# nrf54h20_sysctrl register map
Vendor: Nordic Semiconductor; Series: nRF54h; File version: 1
Registers are 32-bit, read-write, reset 0x0 unless marked. A register's access mark holds for its fields unless they carry their own. Offsets are from the block's base; [hi:lo] are bit positions; lines under a group give offsets from that group; {n}, {i} and the like mark numbered series; 'fields as' and 'values as' point back to an identical list.

## GRCCONF
Base 0x5F940000
{0x100+4i} EVENTS_GRCPERIPH0[{i}] (i=0..31) — Description collection: Event indicating that interrupt triggered for GRC peripheral identifier [n]
  [0] EVENTS_GRCPERIPH0 — Event indicating that interrupt triggered for GRC peripheral identifier [n]
    0=NotGenerated (Event not generated); 1=Generated (Event generated)
{0x180+4i} EVENTS_GRCPERIPH1[{i}] (i=0..31) — Description collection: Event indicating that interrupt triggered for GRC peripheral identifier [32 + n]
  [0] EVENTS_GRCPERIPH1 — Event indicating that interrupt triggered for GRC peripheral identifier [32 + n]
    values as EVENTS_GRCPERIPH0[0].EVENTS_GRCPERIPH0
0x200 EVENTS_SYSTEMOFFREADY — Event indicating that the device is ready to go to System OFF
  [0] EVENTS_SYSTEMOFFREADY
    values as EVENTS_GRCPERIPH0[0].EVENTS_GRCPERIPH0
0x204 EVENTS_SYSTEMOFFNOTREADY — Event indicating that the device is not ready to go to System OFF
  [0] EVENTS_SYSTEMOFFNOTREADY
    values as EVENTS_GRCPERIPH0[0].EVENTS_GRCPERIPH0
0x208 EVENTS_SYSTEMOFFLOCALDOMAINOFF — Event indicating that SYSTEMOFF is non-zero and all local power domains are powered off with the possible exception of Secure Domain depending on the value of SYSTEMOFF.SYSTEMOFFIGNORESECDOM.
  [0] EVENTS_SYSTEMOFFLOCALDOMAINOFF
    values as EVENTS_GRCPERIPH0[0].EVENTS_GRCPERIPH0
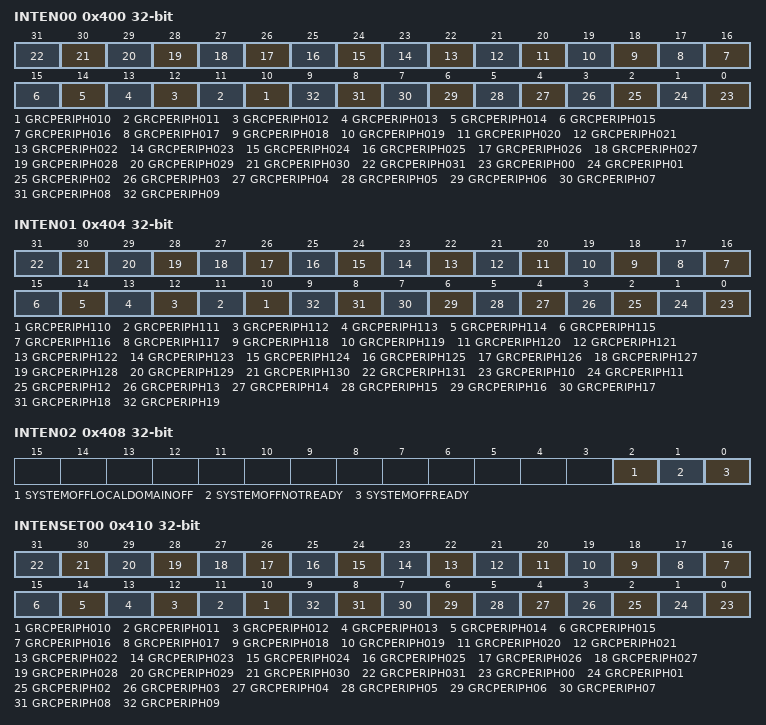
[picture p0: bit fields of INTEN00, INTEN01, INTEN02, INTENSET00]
0x400 INTEN00 — Enable or disable interrupt
  [all] fields
    0=Disabled; 1=Enabled
  [n] GRCPERIPH{n:03} (n=10..31) — Enable or disable interrupt for event GRCPERIPH0[{n}]
  [n] GRCPERIPH{n:02} (n=0..9) — Enable or disable interrupt for event GRCPERIPH0[{n}]
0x404 INTEN01 — Enable or disable interrupt
  [all] fields
    0=Disabled; 1=Enabled
  [n-100] GRCPERIPH{n} (n=110..131) — Enable or disable interrupt for event GRCPERIPH1[{n-100}]
  [n-10] GRCPERIPH{n} (n=10..19) — Enable or disable interrupt for event GRCPERIPH1[{n-10}]
0x408 INTEN02 — Enable or disable interrupt
  [all] fields
    0=Disabled; 1=Enabled
  [2] SYSTEMOFFLOCALDOMAINOFF — Enable or disable interrupt for event SYSTEMOFFLOCALDOMAINOFF
  [1] SYSTEMOFFNOTREADY — Enable or disable interrupt for event SYSTEMOFFNOTREADY
  [0] SYSTEMOFFREADY — Enable or disable interrupt for event SYSTEMOFFREADY
0x410 INTENSET00 — Enable interrupt
  [all] fields
    on read: 0=Disabled (Read: Disabled); 1=Enabled (Read: Enabled) | on write: 1=Set (Enable)
  [n] GRCPERIPH{n:03} (n=10..31) — Write '1' to enable interrupt for event GRCPERIPH0[{n}]
  [n] GRCPERIPH{n:02} (n=0..9) — Write '1' to enable interrupt for event GRCPERIPH0[{n}]
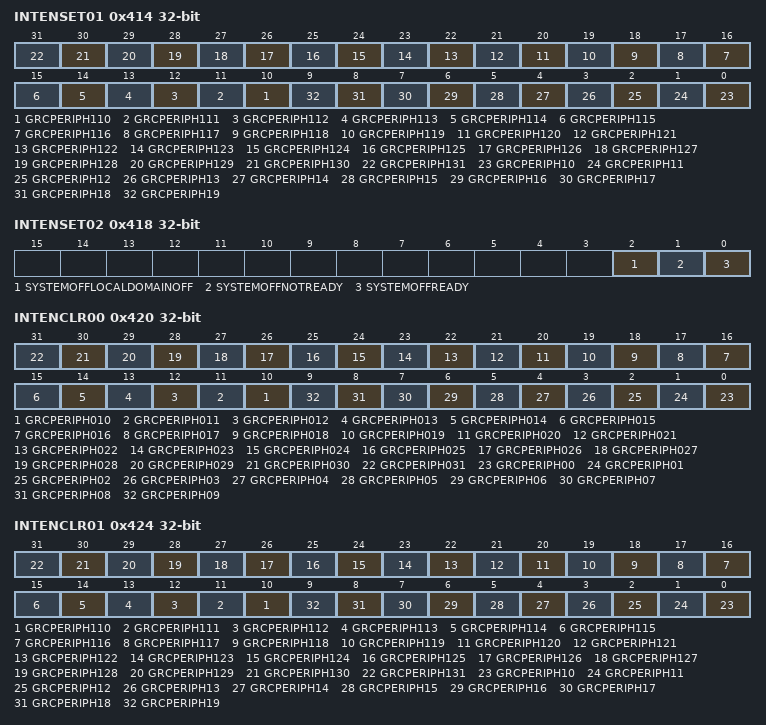
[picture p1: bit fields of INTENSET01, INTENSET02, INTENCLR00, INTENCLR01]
0x414 INTENSET01 — Enable interrupt
  [all] fields
    values as the fields of INTENSET00
  [n-100] GRCPERIPH{n} (n=110..131) — Write '1' to enable interrupt for event GRCPERIPH1[{n-100}]
  [n-10] GRCPERIPH{n} (n=10..19) — Write '1' to enable interrupt for event GRCPERIPH1[{n-10}]
0x418 INTENSET02 — Enable interrupt
  [all] fields
    values as the fields of INTENSET00
  [2] SYSTEMOFFLOCALDOMAINOFF — Write '1' to enable interrupt for event SYSTEMOFFLOCALDOMAINOFF
  [1] SYSTEMOFFNOTREADY — Write '1' to enable interrupt for event SYSTEMOFFNOTREADY
  [0] SYSTEMOFFREADY — Write '1' to enable interrupt for event SYSTEMOFFREADY
0x420 INTENCLR00 — Disable interrupt
  [all] fields
    on read: 0=Disabled (Read: Disabled); 1=Enabled (Read: Enabled) | on write: 1=Clear (Disable)
  [n] GRCPERIPH{n:03} (n=10..31) — Write '1' to disable interrupt for event GRCPERIPH0[{n}]
  [n] GRCPERIPH{n:02} (n=0..9) — Write '1' to disable interrupt for event GRCPERIPH0[{n}]
0x424 INTENCLR01 — Disable interrupt
  [all] fields
    values as the fields of INTENCLR00
  [n-100] GRCPERIPH{n} (n=110..131) — Write '1' to disable interrupt for event GRCPERIPH1[{n-100}]
  [n-10] GRCPERIPH{n} (n=10..19) — Write '1' to disable interrupt for event GRCPERIPH1[{n-10}]
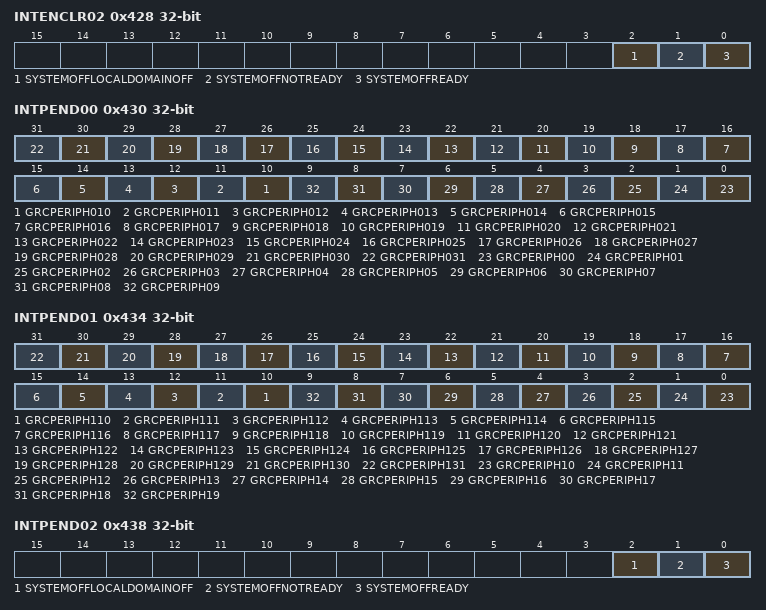
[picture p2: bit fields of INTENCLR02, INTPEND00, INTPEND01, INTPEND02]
0x428 INTENCLR02 — Disable interrupt
  [all] fields
    values as the fields of INTENCLR00
  [2] SYSTEMOFFLOCALDOMAINOFF — Write '1' to disable interrupt for event SYSTEMOFFLOCALDOMAINOFF
  [1] SYSTEMOFFNOTREADY — Write '1' to disable interrupt for event SYSTEMOFFNOTREADY
  [0] SYSTEMOFFREADY — Write '1' to disable interrupt for event SYSTEMOFFREADY
0x430 INTPEND00 ro — Pending interrupts
  [all] fields
    on read: 0=NotPending (Read: Not pending); 1=Pending (Read: Pending)
  [n] GRCPERIPH{n:03} (n=10..31) — Read pending status of interrupt for event GRCPERIPH0[{n}]
  [n] GRCPERIPH{n:02} (n=0..9) — Read pending status of interrupt for event GRCPERIPH0[{n}]
0x434 INTPEND01 ro — Pending interrupts
  [all] fields
    values as the fields of INTPEND00
  [n-100] GRCPERIPH{n} (n=110..131) — Read pending status of interrupt for event GRCPERIPH1[{n-100}]
  [n-10] GRCPERIPH{n} (n=10..19) — Read pending status of interrupt for event GRCPERIPH1[{n-10}]
0x438 INTPEND02 ro — Pending interrupts
  [all] fields
    values as the fields of INTPEND00
  [2] SYSTEMOFFLOCALDOMAINOFF — Read pending status of interrupt for event SYSTEMOFFLOCALDOMAINOFF
  [1] SYSTEMOFFNOTREADY — Read pending status of interrupt for event SYSTEMOFFNOTREADY
  [0] SYSTEMOFFREADY — Read pending status of interrupt for event SYSTEMOFFREADY
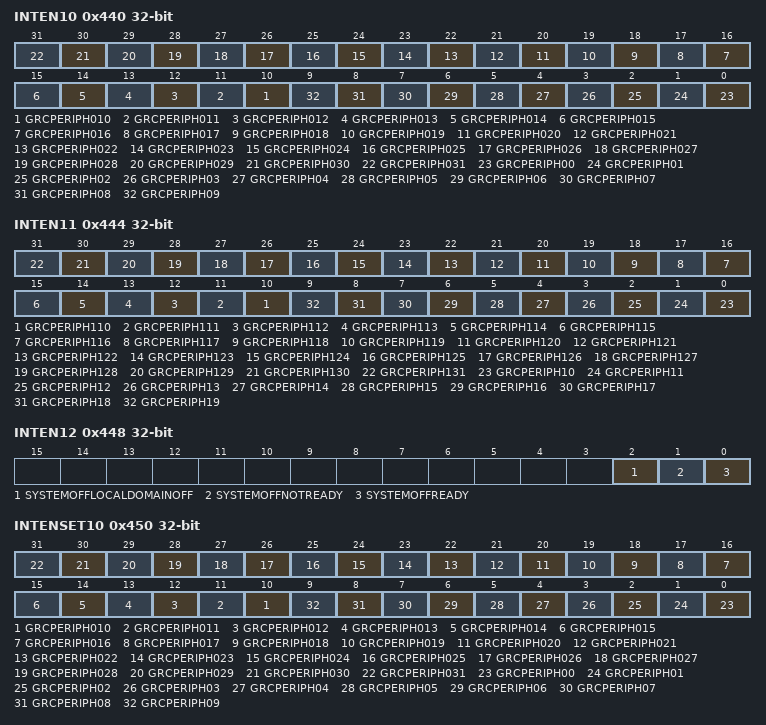
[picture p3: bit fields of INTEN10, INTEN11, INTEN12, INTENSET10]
0x440 INTEN10 — Enable or disable interrupt
  fields as INTEN00
0x444 INTEN11 — Enable or disable interrupt
  fields as INTEN01
0x448 INTEN12 — Enable or disable interrupt
  fields as INTEN02
0x450 INTENSET10 — Enable interrupt
  fields as INTENSET00
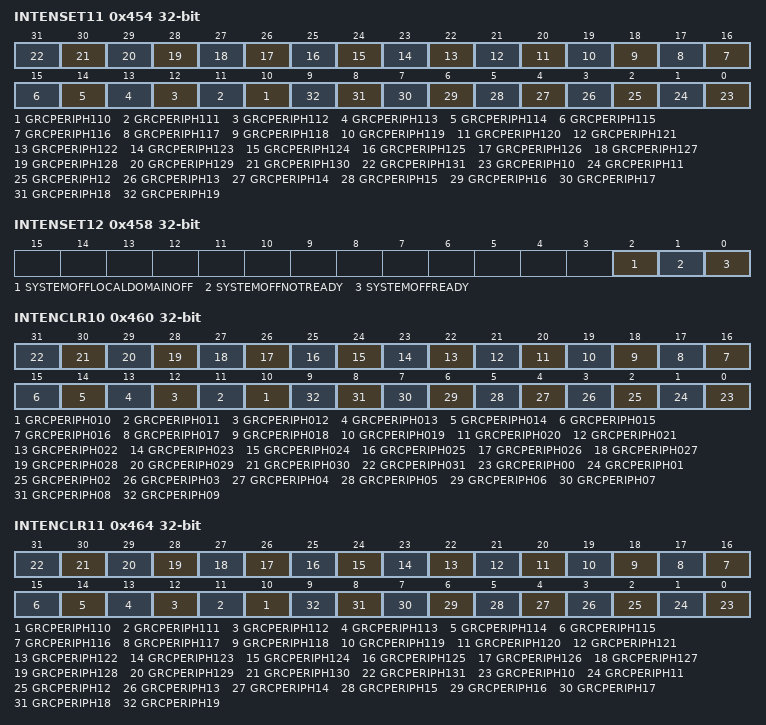
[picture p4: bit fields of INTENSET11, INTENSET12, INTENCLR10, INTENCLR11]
0x454 INTENSET11 — Enable interrupt
  fields as INTENSET01
0x458 INTENSET12 — Enable interrupt
  fields as INTENSET02
0x460 INTENCLR10 — Disable interrupt
  fields as INTENCLR00
0x464 INTENCLR11 — Disable interrupt
  fields as INTENCLR01
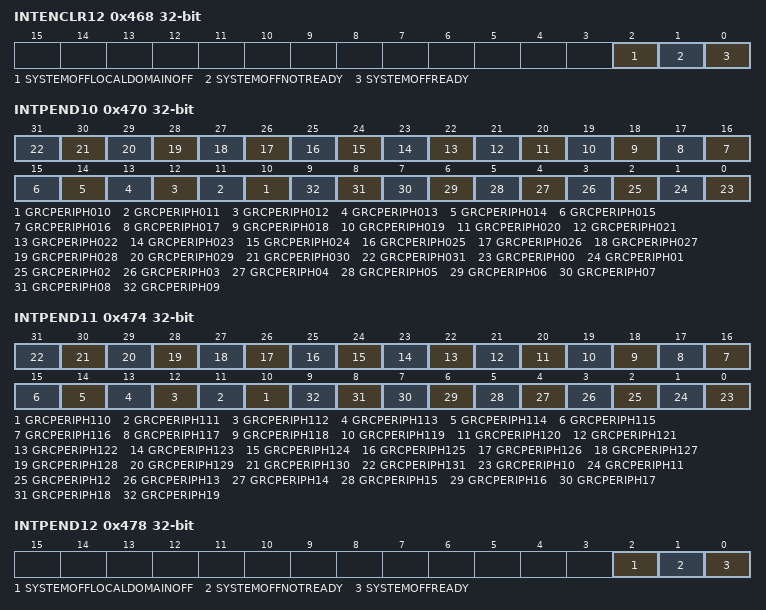
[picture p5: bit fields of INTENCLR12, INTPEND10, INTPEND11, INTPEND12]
0x468 INTENCLR12 — Disable interrupt
  fields as INTENCLR02
0x470 INTPEND10 ro — Pending interrupts
  fields as INTPEND00
0x474 INTPEND11 ro — Pending interrupts
  fields as INTPEND01
0x478 INTPEND12 ro — Pending interrupts
  fields as INTPEND02
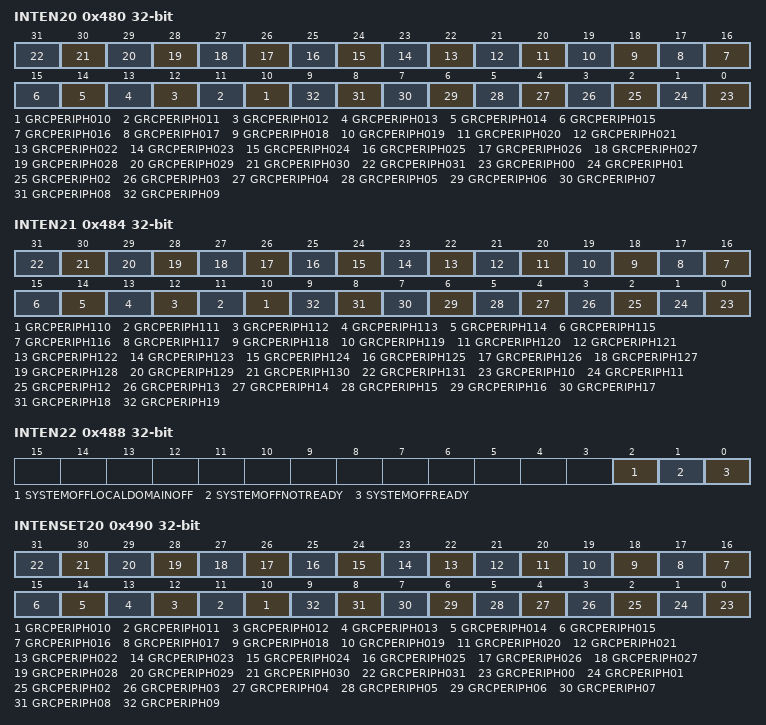
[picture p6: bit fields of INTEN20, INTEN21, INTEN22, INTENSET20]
0x480 INTEN20 — Enable or disable interrupt
  fields as INTEN00
0x484 INTEN21 — Enable or disable interrupt
  fields as INTEN01
0x488 INTEN22 — Enable or disable interrupt
  fields as INTEN02
0x490 INTENSET20 — Enable interrupt
  fields as INTENSET00
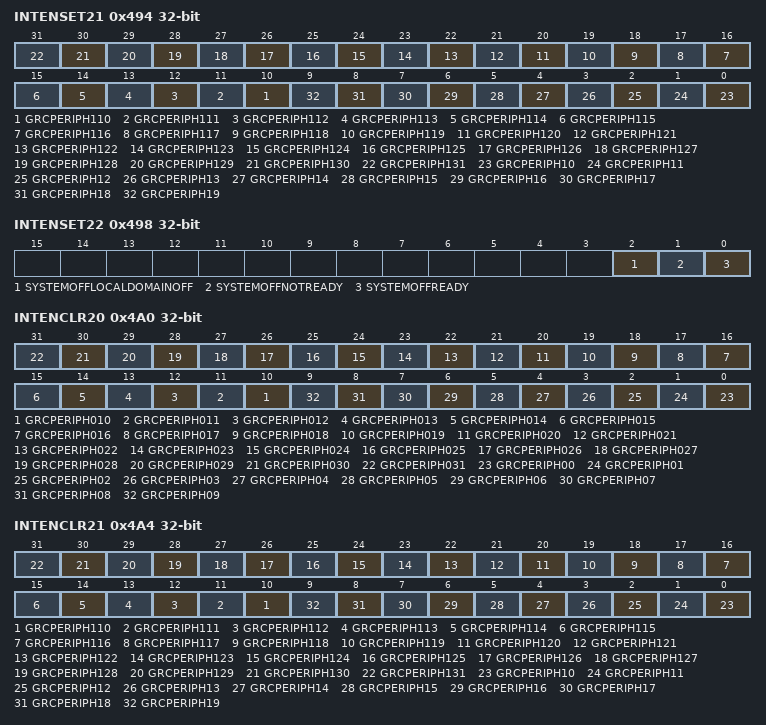
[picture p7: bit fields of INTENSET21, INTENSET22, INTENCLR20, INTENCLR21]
0x494 INTENSET21 — Enable interrupt
  fields as INTENSET01
0x498 INTENSET22 — Enable interrupt
  fields as INTENSET02
0x4A0 INTENCLR20 — Disable interrupt
  fields as INTENCLR00
0x4A4 INTENCLR21 — Disable interrupt
  fields as INTENCLR01
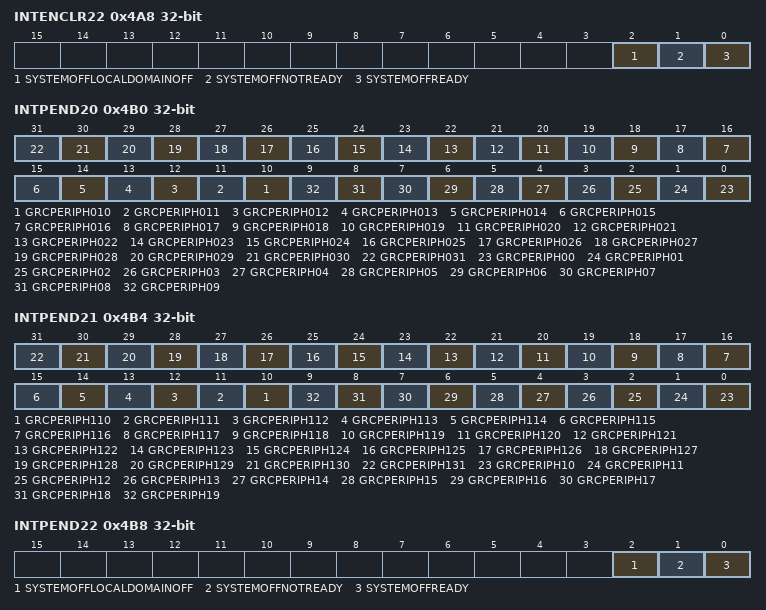
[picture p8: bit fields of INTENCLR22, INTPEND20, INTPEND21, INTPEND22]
0x4A8 INTENCLR22 — Disable interrupt
  fields as INTENCLR02
0x4B0 INTPEND20 ro — Pending interrupts
  fields as INTPEND00
0x4B4 INTPEND21 ro — Pending interrupts
  fields as INTPEND01
0x4B8 INTPEND22 ro — Pending interrupts
  fields as INTPEND02
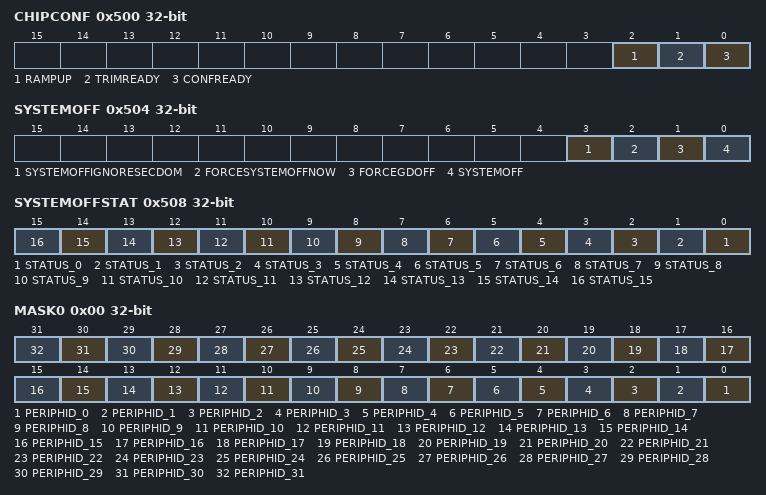
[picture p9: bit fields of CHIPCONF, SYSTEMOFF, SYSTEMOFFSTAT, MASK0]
0x500 CHIPCONF — Chip configuration
  [2] RAMPUP write-1-sets — Ramp up done status
    0=NotDone (Ramp up is not done); 1=Done (Ramp up is done)
  [1] TRIMREADY write-1-sets — Trim configuration ready
    0=NotReady (Trim configuration is not ready); 1=Ready (Trim configuration is completed)
  [0] CONFREADY write-1-sets — Chip configuration ready
    0=NotReady (Chip configuration is not ready); 1=Ready (Chip configuration is completed)
0x504 SYSTEMOFF wo
  [3] SYSTEMOFFIGNORESECDOM — System OFF without considering Secure Domain
    0=Disable (Power state of secure domain is considered for SYSTEMOFFLOCALDOMAINOFF and secure domain is not allowed to wake up again after SYSTEMOFFLOCALDOMAINOFF.); 1=Enable (Power state of secure domain is ignored for SYSTEMOFFLOCALDOMAINOFF and secure domain is allowed to both run during and wake up again after SYSTEMOFFLOCALDOMAINOFF.)
  [2] FORCESYSTEMOFFNOW — Force System OFF mode immediately
    0=NoOperation; 1=Force System OFF mode and power all domains OFF mode immediately except Secure Domain. Secure Domain power itself down before the device enters System Off.
  [1] FORCEGDOFF — Force global domain OFF
    0=NoOperation; 1=Force (Enter into System OFF mode and force global domain off once all local domains are powered down.)
  [0] SYSTEMOFF — Enable System OFF mode
    0=Exit System OFF mode. Local domains are allowed to power on again.; 1=Enter into System OFF mode. Local domains are not allowed to be powered up once they are all powered down.
0x508 SYSTEMOFFSTAT — System OFF status
  [n] STATUS_{n} (n=0..15) — System OFF status for power domain [{n}]
    0=Ready (Power domain [{n}] is ready to go to system OFF); 1=Prevent (Power domain [{n}] is preventing system OFF)
0x50C GRCFORCEON group — Unspecified
  0x00 MASK0 — Mask the active power domain request due to interrupt from GRC peripheral identifier [31:0]
    [n] PERIPHID_{n} (n=0..31) — GRC peripheral identifier [{n}]
      0=Off (The GRC active power domain remain Off even when GRC peripheral [{n}] interrupt is active); 1=On (The GRC active power domain is kept On when GRC peripheral [{n}] interrupt is active)
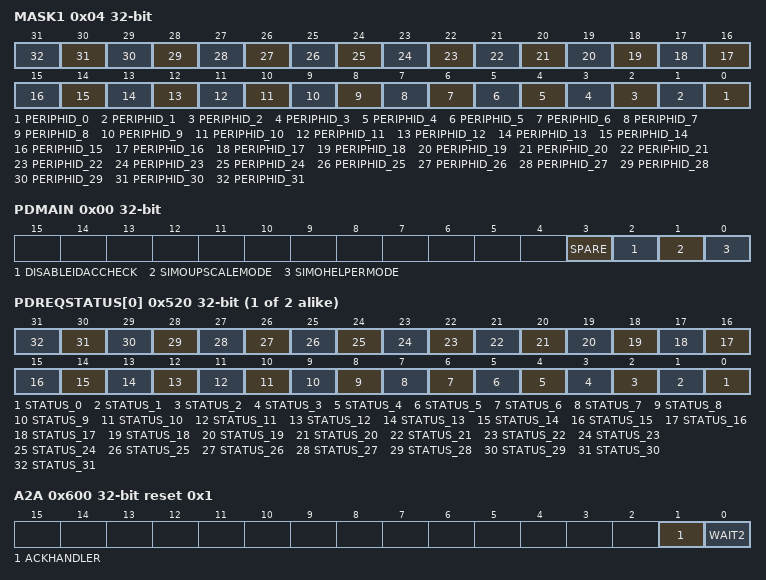
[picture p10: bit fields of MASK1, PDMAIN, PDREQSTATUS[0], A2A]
  0x04 MASK1 — Mask the active power domain request due to interrupt from GRC peripheral identifier [63 : 32]
    [n] PERIPHID_{n} (n=0..31) — GRC peripheral identifier [{n}]
      0=Off (The GRC active power domain remain Off even when GRC peripheral [32 + {n}] interrupt is active); 1=On (The GRC active power domain is kept On when GRC peripheral [32 + {n}] interrupt is active)
0x518 METALFIX group — Unspecified
  0x00 PDMAIN — Register for metal-fixes in GRC Main power domain
    [3] SPARE — Not used
    [2] DISABLEIDACCHECK — Disable HFXO IDAC check
      0=Enabled (IDAC check in HFXO enabled); 1=Disabled (IDAC check in HFXO disabled)
    [1] SIMOUPSCALEMODE — SIMO upscale mode configuration
      0=Disable (Legacy mode. Only PWM_HELPER or HP_RADIO high power modes will request UPSCALE mode from LDO1V0); 1=Enable (All high power modes will request UPSCALE helper mode from LDO1V0)
    [0] SIMOHELPERMODE — SIMO helper mode configuration
      0=Enable (All high power modes will request nominal helper mode except UPSCALE modes(PWM_HELPER or HP_RADIO) which will request radio helper mode from LDO1V0); 1=Disable (Legacy mode. Only SIMO UPSCALE modes(PWM_HELPER or HP_RADIO) will request helper mode from LDO1V0 (nominal helper mode))
  0x04 PDACT — Register for possible metal-fix in GRC Active power domain
    [31:0] VAL — Value
{0x520+4i} PDREQSTATUS[{i}] (i=0..1) — Description collection: Power domain request status
  [all] fields
    0=Inactive (Power domain request is inactive); 1=Active (Power domain request is active)
  [n] STATUS_{n} ro (n=0..31) — The power domain request status for power domain [n] * 32 + [{n}]
0x530 PORBORRESET — Enable PORBOR type global reset
  [0] ENABLE — Global reset will trigger PORBOR type reset in analog reset controller
    0=Disabled (Reset feature disabled); 1=Enabled (Reset feature enabled)
0x600 A2A reset 0x1 — Control for analog-to-asynchronous components
  [1] ACKHANDLER
    0=Disabled (Asynchronous request acknowledge handler is disabled.); 1=Enabled (Asynchronous request acknowledge handler is enabled.)
  [0] WAIT2
    0=Enabled (Wait2 elements are enabled.); 1=Disabled (Wait2 elements are disabled.)

## Notices in the file
Copyright (c) 2010 - 2024, Nordic Semiconductor ASA
All rights reserved.
Redistribution and use in source and binary forms, with or without modification,
are permitted provided that the following conditions are met:
1. Redistributions of source code must retain the above copyright notice, this
list of conditions and the following disclaimer.
2. Redistributions in binary form, except as embedded into a Nordic
Semiconductor ASA integrated circuit in a product or a software update for
such product, must reproduce the above copyright notice, this list of
conditions and the following disclaimer in the documentation and/or other
materials provided with the distribution.
3. Neither the name of Nordic Semiconductor ASA nor the names of its
contributors may be used to endorse or promote products derived from this
software without specific prior written permission.
4. This software, with or without modification, must only be used with a
Nordic Semiconductor ASA integrated circuit.
5. Any software provided in binary form under this license must not be reverse
engineered, decompiled, modified and/or disassembled.
THIS SOFTWARE IS PROVIDED BY NORDIC SEMICONDUCTOR ASA "AS IS" AND ANY EXPRESS
OR IMPLIED WARRANTIES, INCLUDING, BUT NOT LIMITED TO, THE IMPLIED WARRANTIES
OF MERCHANTABILITY, NONINFRINGEMENT, AND FITNESS FOR A PARTICULAR PURPOSE ARE
DISCLAIMED. IN NO EVENT SHALL NORDIC SEMICONDUCTOR ASA OR CONTRIBUTORS BE
LIABLE FOR ANY DIRECT, INDIRECT, INCIDENTAL, SPECIAL, EXEMPLARY, OR
CONSEQUENTIAL DAMAGES (INCLUDING, BUT NOT LIMITED TO, PROCUREMENT OF SUBSTITUTE
GOODS OR SERVICES; LOSS OF USE, DATA, OR PROFITS; OR BUSINESS INTERRUPTION)
HOWEVER CAUSED AND ON ANY THEORY OF LIABILITY, WHETHER IN CONTRACT, STRICT
LIABILITY, OR TORT (INCLUDING NEGLIGENCE OR OTHERWISE) ARISING IN ANY WAY OUT
OF THE USE OF THIS SOFTWARE, EVEN IF ADVISED OF THE POSSIBILITY OF SUCH DAMAGE.
